# GD32H77x_78x register map
File version: 1.0
CPU: CM7 r1p2, little endian, MPU, FPU, 4 interrupt priority bits
Registers are 32-bit, read-write, reset 0x0 unless marked. A register's access mark holds for its fields unless they carry their own. Offsets are from the block's base; [hi:lo] are bit positions; {n}, {i} and the like mark numbered series.

## DMAMUX — DMA request multiplexer
Base 0x40020800
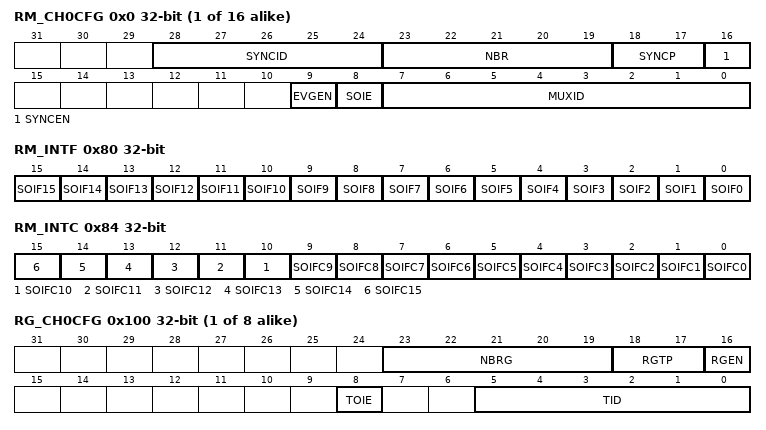
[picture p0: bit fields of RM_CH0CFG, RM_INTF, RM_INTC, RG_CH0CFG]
{0x0+4i} RM_CH{i}CFG (i=0..15) — Request multiplexer channel {i} configuration regist
  [28:24] SYNCID — Synchronization input identification
  [23:19] NBR — Number of DMA requests to forward
  [18:17] SYNCP — Synchronization input polarity
  [16] SYNCEN — Synchronization enable
  [9] EVGEN — Event generation enable
  [8] SOIE — Synchronization overrun interrupt enable
  [7:0] MUXID — Multiplexer input identification
0x80 RM_INTF ro — Request multiplexer channel interrupt flag register
  [n] SOIF{n} (n=0..15) — Synchronization overrun event flag of request multiplexer channel {n}
0x84 RM_INTC wo — Request multiplexer channel interrupt flag clear register
  [n] SOIFC{n} (n=0..15) — Clear bit for synchronization overrun event flag of request multiplexer channel {n}
{0x100+4i} RG_CH{i}CFG (i=0..7) — Request generator channel {i} configuration regist
  [23:19] NBRG — Number of DMA requests to be generated
  [18:17] RGTP — DMAMUX request generator trigger polarity
  [16] RGEN — DMAMUX request generator channel x enable
  [8] TOIE — Trigger overrun interrupt enable
  [5:0] TID — Trigger input identification
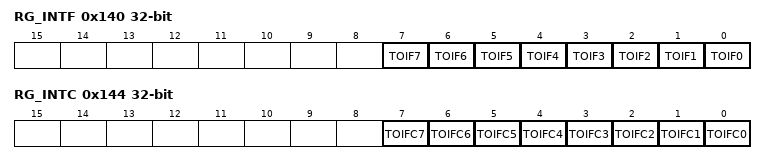
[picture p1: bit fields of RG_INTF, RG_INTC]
0x140 RG_INTF ro — Request generator channel interrupt flag register
  [n] TOIF{n} (n=0..7) — Trigger overrun event flag of request generator channel {n}
0x144 RG_INTC wo — Rquest generator channel interrupt flag clear register
  [n] TOIFC{n} (n=0..7) — Clear bit for trigger overrun event flag of request generator channel {n}

## EDOUT — En-coder Divided-Output controller
Base 0x40018800
0x00 CTL — Control register
  [0] POL — The active polarity of the B-phase output signal selection
0x04 ENABLE
  [0] EDOUTEN — EDOUT enable bit
0x08 LOC — Location register
  [15:0] LOCMAX — This bits set the maximum location value for one rotation
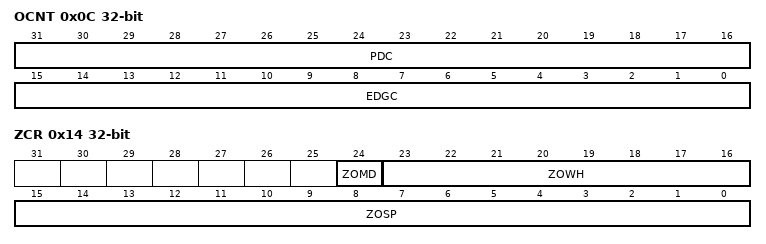
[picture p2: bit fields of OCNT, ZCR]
0x0C OCNT — Output counter register
  [31:16] PDC — These bits set the phase difference between the A-phase signal and the B-phase signal for the next carrier cycle
  [15:0] EDGC — These bits set the number of edges of the A-phase signal and the B-phase signal for the next carrier cycle
0x10 LCNT — Location counter register
  [15:0] LOCCNT — These bits are used to set the current position value
0x14 ZCR — Z-PHASE configure register
  [24] ZOMD — Z-PHASE output mode
  [23:16] ZOWH — Z-PHASE output width
  [15:0] ZOSP — Z-PHASE output start position

## ENET0_MAC_FCTH — MAC flow control threshold register
Base 0x40029080
Same registers: ENET1_MAC_FCTH 0x4002B080
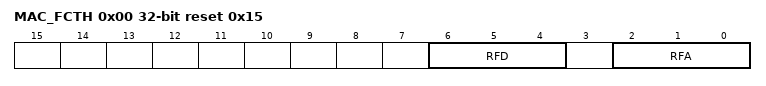
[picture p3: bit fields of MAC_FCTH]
0x00 MAC_FCTH reset 0x15 — Ethernet MAC flow control threshold register
  [6:4] RFD — Threshold of deactive flow control
  [2:0] RFA — Threshold of active flow control

## ENET0_MSC — Ethernet: MAC statistics counters
Base 0x40028100
Same registers: ENET1_MSC 0x4002A100
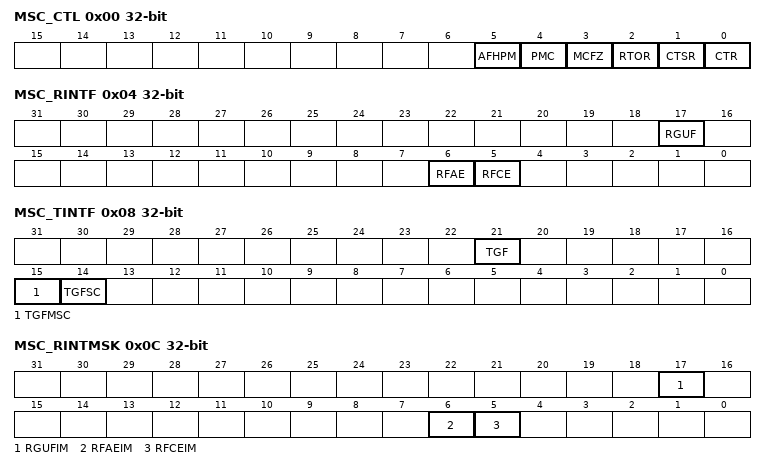
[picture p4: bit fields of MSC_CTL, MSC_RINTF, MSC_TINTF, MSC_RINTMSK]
0x00 MSC_CTL — Ethernet MSC control register (MSC_CTL)
  [5] AFHPM — Almost full or half preset mode
  [4] PMC wo — Preset MSC counter
  [3] MCFZ — MSC counter freeze
  [2] RTOR — Reset on read
  [1] CTSR — Counter stop rollover
  [0] CTR — Counter reset
0x04 MSC_RINTF ro — Ethernet MSC receive interrupt flag register (MSC_RINTF)
  [17] RGUF — Received Good Unicast Frames
  [6] RFAE — Received frames alignment error
  [5] RFCE — Received frames CRC error
0x08 MSC_TINTF ro — Ethernet MSC transmit interrupt flag register (MSC_TINTF)
  [21] TGF — Transmitted good frames
  [15] TGFMSC — Transmitted good frames more single collision
  [14] TGFSC — Transmitted good frames single collision
0x0C MSC_RINTMSK — Ethernet MSC receive interrupt mask register (MSC_RINTMSK)
  [17] RGUFIM — Received good unicast frames interrupt mask
  [6] RFAEIM — Received frames alignment error interrupt mask
  [5] RFCEIM — Received frame CRC error interrupt mask
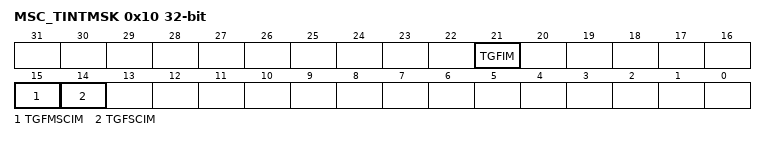
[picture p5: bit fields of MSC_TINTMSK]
0x10 MSC_TINTMSK — Ethernet MSC transmit interrupt mask register (MSC_TINTMSK)
  [21] TGFIM — Transmitted good frames interrupt mask
  [15] TGFMSCIM — Transmitted good frames more single interrupt collision mask
  [14] TGFSCIM — Transmitted good frames single collision interrupt mask
0x4C MSC_SCCNT ro — Ethernet MSC transmitted good frames after a single collision counter
  [31:0] SCC — Transmitted good frames after a single collision counter
0x50 MSC_MSCCNT ro — Ethernet MSC transmitted good frames after more than a single collision
  [31:0] MSCC — Transmitted good frames after more than a single collision counter
0x68 MSC_TGFCNT ro — Ethernet MSC transmitted good frames counter register
  [31:0] TGF — Transmitted good frames counter
0x94 MSC_RFCECNT ro — Ethernet MSC received frames with CRC error counter register
  [31:0] RFCER — Received frames with CRC error counter
0x98 MSC_RFAECNT ro — Ethernet MSC received frames with alignment error counter register
  [31:0] RFAER — Received frames with alignment error counter
0xC4 MSC_RGUFCNT ro — MSC received good unicast frames counter register
  [31:0] RGUF — Received good unicast frames counter
